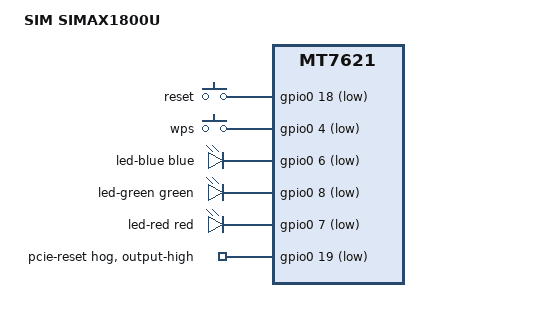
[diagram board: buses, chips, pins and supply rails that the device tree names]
// SPDX-License-Identifier: GPL-2.0-or-later

/dts-v1/;

#include "mt7621.dtsi"

#include <dt-bindings/gpio/gpio.h>
#include <dt-bindings/input/input.h>
#include <dt-bindings/leds/common.h>

/ {
	compatible = "sim,simax1800u", "mediatek,mt7621-soc";
	model = "SIM SIMAX1800U";

	aliases {
		serial0 = &uart0;
	};

	chosen {
		stdout-path = &uart0;
	};

	config {
		boot-btn1 = "reset";
		boot-btn2 = "wps";
		boot-led1 = "green:status";
		boot-led2 = "red:status";
		bootcmd_1-1 = "tftp_load_initramfs_loop";
		bootcmd_1-2 = "tftp_restore_system_loop";
		bootcmd_1-3 = "config_netconsole";
		bootcmd_2-1 = "tftp_load_initramfs_loop";
		bootcmd_2-2 = "tftp_restore_system_loop";
		bootcmd_2-3 = "config_netconsole";
	};

	gpio-keys {
		compatible = "gpio-keys";

		button-reset {
			label = "reset";
			gpios = <&gpio0 18 GPIO_ACTIVE_LOW>;
			linux,code = <KEY_RESTART>;
		};

		button-wps {
			label = "wps";
			gpios = <&gpio0 4 GPIO_ACTIVE_LOW>;
			linux,code = <KEY_WPS_BUTTON>;
		};
	};

	gpio-leds {
		compatible = "gpio-leds";

		led-blue {
			color = <LED_COLOR_ID_BLUE>;
			function = LED_FUNCTION_STATUS;
			gpios = <&gpio0 6 GPIO_ACTIVE_LOW>;
			default-state = "off";
		};

		led-green {
			color = <LED_COLOR_ID_GREEN>;
			function = LED_FUNCTION_STATUS;
			gpios = <&gpio0 8 GPIO_ACTIVE_LOW>;
			default-state = "on";
		};

		led-red {
			color = <LED_COLOR_ID_RED>;
			function = LED_FUNCTION_STATUS;
			gpios = <&gpio0 7 GPIO_ACTIVE_LOW>;
			default-state = "off";
		};
	};
};

&gpio0 {
	pcie-reset {
		gpio-hog;
		gpios = <19 GPIO_ACTIVE_LOW>;
		output-high;
	};
};

&state_default {
	/delete-node/ rgmii2-gpio_pins;
	/delete-node/ sdxc-gpio_pins;
};
